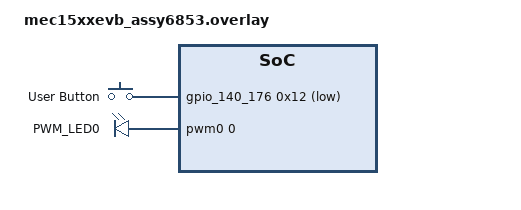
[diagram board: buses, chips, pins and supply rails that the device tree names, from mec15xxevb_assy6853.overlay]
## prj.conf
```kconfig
CONFIG_GPIO=y



# CONFIG_STDOUT_CONSOLE=y
# CONFIG_PRINTK=y
# CONFIG_PWM=y
# CONFIG_LOG=y
# CONFIG_LOG_PRINTK=y
# CONFIG_LOG_MODE_IMMEDIATE=y
# CONFIG_PWM_LOG_LEVEL_DBG=y
```

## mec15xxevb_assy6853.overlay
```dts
// To get started, press Ctrl+Space to bring up the completion menu and view the available nodes.

// You can also use the buttons in the sidebar to perform actions on nodes.
// Actions currently available include:

// * Enabling / disabling the node
// * Adding the bus to a bus
// * Removing the node
// * Connecting ADC channels

// For more help, browse the DeviceTree documentation at https://docs.zephyrproject.org/latest/guides/dts/index.html
// You can also visit the nRF DeviceTree extension documentation at https://docs.nordicsemi.com/bundle/nrf-connect-vscode/page/guides/ncs_configure_app.html#devicetree-support-in-the-extension





/ {
    aliases {
        sw0 = &button0;  /* Alias for the button */
    };
       
    buttons {
        compatible = "gpio-keys";
        button0: button_0 {
            gpios = <&gpio_140_176 0x12 (GPIO_ACTIVE_LOW | GPIO_PULL_UP)>;
            label = "User Button";
        };
    };


    pwmleds {
        compatible = "pwm-leds";
    
        pwm_led0: pwm_led_0 {
            pwms = <&pwm0 0 20000000 0>; /* Channel 0, Period 20ms, Normal Polarity */
            label = "PWM_LED0";
        };
    };

};



// / {
//     aliases {
//         sw0 = &button0;  /* Alias for the button */
//     };
       
//     buttons {
//         compatible = "gpio-keys";
//         button0: button_0 {
//             gpios = <&gpio_140_176 0x12 (GPIO_ACTIVE_LOW | GPIO_PULL_UP)>;
//             label = "User Button";
//         };
//     };

//     pwmleds {
//         compatible = "pwm-leds";
    
//         pwm_led0: pwm_led_0 {
//             pwms = <&pwm0 0 20000000 PWM_POLARITY_NORMAL>; /* Channel 0, Period 20ms, Normal Polarity */
//             label = "PWM_LED0";
//         };
//     };
// };



// &pwm0 { 
//     status = "okay";
// };

// &pwmleds {
//     compatible = "pwm-leds";

//     pwm_led0: pwm_led_0 {
//         pwms = <&pwm0 0 20000000 0>; /* Channel 0, Period 20ms, Normal Polarity */
//         label = "PWM_LED0";
//     };
// };
```

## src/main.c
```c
/*
 * Copyright (c) 2016 Open-RnD Sp. z o.o.
 * Copyright (c) 2020 Nordic Semiconductor ASA
 *
 * SPDX-License-Identifier: Apache-2.0
 */

#include <zephyr/kernel.h>
#include <zephyr/device.h>
#include <zephyr/drivers/gpio.h>
#include <zephyr/sys/printk.h>
#include <inttypes.h>

#define SLEEP_TIME_MS 1

/* Button and LED aliases from the devicetree */
#define SW0_NODE DT_ALIAS(sw0)         
#define LED0_NODE DT_ALIAS(led1)      

#if !DT_NODE_HAS_STATUS(SW0_NODE, okay)
#error "Unsupported board: button alias 'sw0' not defined in the device tree"
#endif

#if !DT_NODE_HAS_STATUS(LED0_NODE, okay)
#error "Unsupported board: LED alias 'led0' not defined in the device tree"
#endif

/* Define button and LED devices */
static const struct gpio_dt_spec button = GPIO_DT_SPEC_GET_OR(SW0_NODE, gpios, {0});
static const struct gpio_dt_spec led = GPIO_DT_SPEC_GET_OR(LED0_NODE, gpios, {0});

/* GPIO callback structure */
static struct gpio_callback button_cb_data;

/* Button pressed callback function */
void button_pressed(const struct device *dev, struct gpio_callback *cb, uint32_t pins)
{
    printk("Button pressed on %s at %" PRIu32 "\n", dev->name, k_cycle_get_32());
    printk("inside the button Interuppt");
    /* Toggle the LED */
     k_msleep(SLEEP_TIME_MS);
    gpio_pin_toggle_dt(&led);       
}

int main(void)
{
    int ret;
      printk("Hello Surjit");
    /* Configure the LED as an output */
    if (!device_is_ready(led.port)) {
        printk("Error: LED device %s is not ready\n", led.port->name);
        return -1;
    }
    ret = gpio_pin_configure_dt(&led, GPIO_OUTPUT_ACTIVE);
    if (ret != 0) {
        printk("Error %d: failed to configure LED %s pin %d\n", ret, led.port->name, led.pin);
        return ret;
    }

    /* Configure the button as an input with interrupt */
    if (!device_is_ready(button.port)) {
        printk("Error: Button device %s is not ready\n", button.port->name);
        return -1;
    }
    ret = gpio_pin_configure_dt(&button, GPIO_INPUT);
    if (ret != 0) {
        printk("Error %d: failed to configure button %s pin %d\n", ret, button.port->name, button.pin);
        return ret;
    }
    ret = gpio_pin_interrupt_configure_dt(&button, GPIO_INT_EDGE_TO_ACTIVE);
    if (ret != 0) { 
        printk("Error %d: failed to configure interrupt for button %s pin %d\n", ret, button.port->name, button.pin);
        return ret;
    }

    /* Initialize button callback */
    gpio_init_callback(&button_cb_data, button_pressed, BIT(button.pin));
    gpio_add_callback(button.port, &button_cb_data);
    printk("Set up button on %s pin %d\n", button.port->name, button.pin);
    printk("Set up LED on %s pin %d\n", led.port->name, led.pin);

    /* Main loop */
    while (1) {
        k_msleep(SLEEP_TIME_MS);
    }

    return 0;
}


// #include <zephyr/kernel.h>
// #include <zephyr/sys/printk.h>
// #include <zephyr/device.h>
// #include <zephyr/drivers/pwm.h>

// static const struct pwm_dt_spec pwm_led0 = PWM_DT_SPEC_GET(DT_ALIAS(pwm_led0));

// #define MIN_PERIOD PWM_MSEC(1)
// #define MAX_PERIOD PWM_SEC(1U)

// void main(void) {
//     printk("PWM LED Control Example\n");

//     if (!pwm_is_ready_dt(&pwm_led0)) {
//         printk("Error: PWM device is not ready\n");
//         return;
//     }

//     uint32_t period = MAX_PERIOD;
//     uint8_t dir = 0; /* Direction of change: 0 = decrease, 1 = increase */

//     while (1) {
//         pwm_set_dt(&pwm_led0, period, period / 2);
//         printk("PWM Period: %u\n", period);

//         if (dir) {
//             period *= 2;
//             if (period > MAX_PERIOD) {
//                 period = MAX_PERIOD / 2;
//                 dir = 0;
//             }
//         } else {
//             period /= 2;
//             if (period < MIN_PERIOD) {
//                 period = MIN_PERIOD * 2;
//                 dir = 1;
//             }
//         }

//         k_sleep(K_MSEC(500)); /* Adjust delay as needed */
//     }
// }
```
